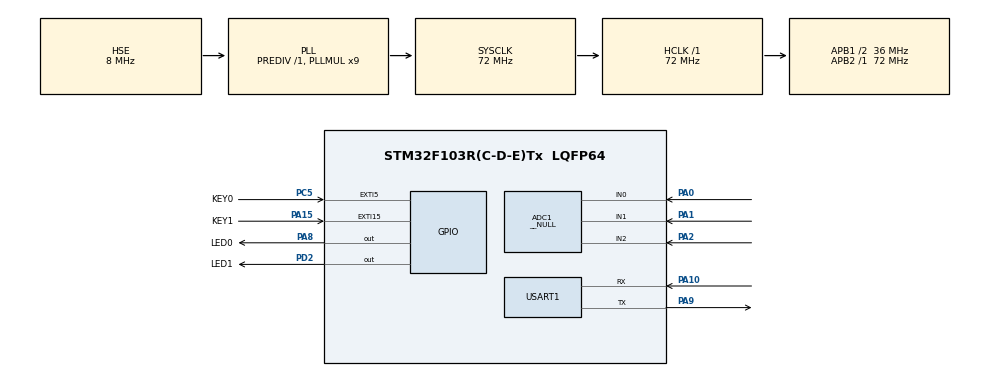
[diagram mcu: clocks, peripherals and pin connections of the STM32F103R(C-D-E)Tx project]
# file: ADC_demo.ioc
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Mcu.Family=STM32F1
ADC1.Rank-14\#ChannelRegularConversion=4
VP_ADC1_TempSens_Input.Mode=IN-TempSens
ADC1.ContinuousConvMode=ENABLE
SH.ADCx_IN2.0=ADC1_IN2,IN2
ADC1.Channel-14\#ChannelRegularConversion=ADC_CHANNEL_TEMPSENSOR
RCC.SYSCLKSource=RCC_SYSCLKSOURCE_PLLCLK
ProjectManager.StackSize=0x400
PD1-OSC_OUT.Signal=RCC_OSC_OUT
PA15.GPIO_Label=KEY1
PA15.GPIO_ModeDefaultEXTI=GPIO_MODE_IT_RISING
ADC1.Mode=__NULL
RCC.HCLKFreq_Value=72000000
RCC.APB2TimFreq_Value=72000000
Dma.ADC1.0.Direction=DMA_PERIPH_TO_MEMORY
ADC1.Channel-2\#ChannelRegularConversion=ADC_CHANNEL_2
Dma.ADC1.0.MemDataAlignment=DMA_MDATAALIGN_WORD
RCC.AHBFreq_Value=72000000
NVIC.EXTI15_10_IRQn=true\:0\:0\:false\:false\:true\:true\:true
ADC1.Channel-0\#ChannelRegularConversion=ADC_CHANNEL_0
PB3.Mode=Trace_Asynchronous_SW
RCC.PLLMUL=RCC_PLL_MUL9
ADC1.Rank-2\#ChannelRegularConversion=3
PC14-OSC32_IN.Mode=LSE-External-Oscillator
PA14.Mode=Trace_Asynchronous_SW
Dma.ADC1.0.PeriphInc=DMA_PINC_DISABLE
PA8.Signal=GPIO_Output
SH.ADCx_IN0.0=ADC1_IN0,IN0
ADC1.SamplingTime-0\#ChannelRegularConversion=ADC_SAMPLETIME_55CYCLES_5
Mcu.Package=LQFP64
NVIC.TimeBase=TIM7_IRQn
RCC.EnbaleCSS=true
NVIC.TimeBaseIP=TIM7
PA10.Signal=USART1_RX
PA15.Signal=GPXTI15
SH.ADCx_IN1.0=ADC1_IN1,IN1
RCC.APB1TimFreq_Value=72000000
PC5.Signal=GPXTI5
Dma.Request0=ADC1
NVIC.TIM7_IRQn=true\:0\:0\:false\:false\:true\:false\:true
PA8.PinState=GPIO_PIN_SET
RCC.PLLSourceVirtual=RCC_PLLSOURCE_HSE
PC15-OSC32_OUT.Mode=LSE-External-Oscillator
Dma.ADC1.0.Instance=DMA1_Channel1
ADC1.Rank-0\#ChannelRegularConversion=1
PD1-OSC_OUT.Mode=HSE-External-Oscillator
PA10.Mode=Asynchronous
PD2.GPIO_PuPd=GPIO_PULLDOWN
VP_SYS_VS_tim7.Mode=TIM7
PD0-OSC_IN.Signal=RCC_OSC_IN
RCC.APB1CLKDivider=RCC_HCLK_DIV2
PC14-OSC32_IN.Signal=RCC_OSC32_IN
PC5.GPIO_PuPd=GPIO_PULLUP
ADC1.SamplingTime-2\#ChannelRegularConversion=ADC_SAMPLETIME_55CYCLES_5
PA0-WKUP.Signal=ADCx_IN0
RCC.ADCPresc=RCC_ADCPCLK2_DIV6
PA13.Signal=SYS_JTMS-SWDIO
Dma.ADC1.0.PeriphDataAlignment=DMA_PDATAALIGN_WORD
PA9.Mode=Asynchronous
PA8.GPIO_Label=LED0
ProjectManager.TargetToolchain=STM32CubeIDE
Dma.ADC1.0.Mode=DMA_CIRCULAR
Dma.ADC1.0.Priority=DMA_PRIORITY_LOW
PA9.Signal=USART1_TX
ADC1.Channel-1\#ChannelRegularConversion=ADC_CHANNEL_1
RCC.USBFreq_Value=72000000
PC15-OSC32_OUT.Signal=RCC_OSC32_OUT
PA1.Signal=ADCx_IN1
PC5.GPIO_ModeDefaultEXTI=GPIO_MODE_IT_RISING
PD0-OSC_IN.Mode=HSE-External-Oscillator
PD2.PinState=GPIO_PIN_SET
board=custom
ADC1.SamplingTime-14\#ChannelRegularConversion=ADC_SAMPLETIME_55CYCLES_5
ADC1.EnableAnalogWatchDog=false
RCC.APB2Freq_Value=72000000
ADC1.NbrOfConversion=4
PA13.Mode=Trace_Asynchronous_SW
Mcu.Name=STM32F103R(C-D-E)Tx
PA2.Signal=ADCx_IN2
PB3.Signal=SYS_JTDO-TRACESWO
ADC1.SamplingTime-1\#ChannelRegularConversion=ADC_SAMPLETIME_55CYCLES_5
RCC.SYSCLKFreq_VALUE=72000000
ADC1.master=1
PC5.GPIO_Label=KEY0
USART1.VirtualMode=VM_ASYNC
ADC1.Rank-1\#ChannelRegularConversion=2
NVIC.EXTI9_5_IRQn=true\:0\:0\:false\:false\:true\:true\:true
PA14.Signal=SYS_JTCK-SWCLK
Dma.ADC1.0.MemInc=DMA_MINC_ENABLE
ProjectManager.HeapSize=0x200
PA8.GPIO_PuPd=GPIO_PULLDOWN
NVIC.PriorityGroup=NVIC_PRIORITYGROUP_4
ADC1.NbrOfConversionFlag=1
PA15.GPIO_PuPd=GPIO_PULLUP
NVIC.DMA1_Channel1_IRQn=true\:1\:0\:true\:false\:true\:false\:true
PD2.Signal=GPIO_Output
RCC.APB1Freq_Value=36000000
PD2.GPIO_Label=LED1

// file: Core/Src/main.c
/* USER CODE BEGIN Header */
/**
  ******************************************************************************
  * @file           : main.c
  * @brief          : Main program body
  ******************************************************************************
  * @attention
  *
  * <h2><center>&copy; Copyright (c) 2020 STMicroelectronics.
  * All rights reserved.</center></h2>
  *
  * This software component is licensed by ST under BSD 3-Clause license,
  * the "License"; You may not use this file except in compliance with the
  * License. You may obtain a copy of the License at:
  *                        opensource.org/licenses/BSD-3-Clause
  *
  ******************************************************************************
  */
/* USER CODE END Header */
#include "main.h"
#include "adc.h"
#include "dma.h"
#include "usart.h"
#include "gpio.h"

/* USER CODE BEGIN Includes */
#include "bsp_debug.h"
#include "bsp_led.h"
#include "KalmanFilter.h"
/* USER CODE END Includes */

/* USER CODE BEGIN PV */
__IO uint32_t ADC_value[4] = {0};
float ADC_IN1_value = 0;
uint8_t ADC_IN1_FaultCode = 0;
/* USER CODE END PV */

void SystemClock_Config(void);

int main(void)
{

  /* MCU Configuration--------------------------------------------------------*/

  /* Reset of all peripherals, Initializes the Flash interface and the Systick. */
  HAL_Init();

  /* Configure the system clock */
  SystemClock_Config();

  /* Initialize all configured peripherals */
  MX_GPIO_Init();
  MX_DMA_Init();
  MX_ADC1_Init();
  MX_USART1_UART_Init();
  /* USER CODE BEGIN 2 */
  ADC_KalmanFilter_Init();
  /* USER CODE END 2 */

  /* Infinite loop */
  /* USER CODE BEGIN WHILE */
  if(HAL_ADC_Start_DMA(&hadc1, (uint32_t*)ADC_value, 4) != HAL_OK)
  {
    Error_Handler();
  }

  while (1)
  {
    /* USER CODE END WHILE */

    /* USER CODE BEGIN 3 */
	  ADC_IN1_value = KalmanFilter(&ADC1_IN1_KalmanFilter, (float)ADC_value[0]);
	  ADC_IN1_FaultCode = (uint8_t)(16 * (ADC_IN1_value/4095));
  }
  /* USER CODE END 3 */
}

void SystemClock_Config(void)
{
  RCC_OscInitTypeDef RCC_OscInitStruct = {0};
  RCC_ClkInitTypeDef RCC_ClkInitStruct = {0};
  RCC_PeriphCLKInitTypeDef PeriphClkInit = {0};

  /** Initializes the RCC Oscillators according to the specified parameters
  * in the RCC_OscInitTypeDef structure.
  */
  RCC_OscInitStruct.OscillatorType = RCC_OSCILLATORTYPE_HSE;
  RCC_OscInitStruct.HSEState = RCC_HSE_ON;
  RCC_OscInitStruct.HSEPredivValue = RCC_HSE_PREDIV_DIV1;
  RCC_OscInitStruct.HSIState = RCC_HSI_ON;
  RCC_OscInitStruct.PLL.PLLState = RCC_PLL_ON;
  RCC_OscInitStruct.PLL.PLLSource = RCC_PLLSOURCE_HSE;
  RCC_OscInitStruct.PLL.PLLMUL = RCC_PLL_MUL9;
  if (HAL_RCC_OscConfig(&RCC_OscInitStruct) != HAL_OK)
  {
    Error_Handler();
  }
  /** Initializes the CPU, AHB and APB buses clocks
  */
  RCC_ClkInitStruct.ClockType = RCC_CLOCKTYPE_HCLK|RCC_CLOCKTYPE_SYSCLK
                              |RCC_CLOCKTYPE_PCLK1|RCC_CLOCKTYPE_PCLK2;
  RCC_ClkInitStruct.SYSCLKSource = RCC_SYSCLKSOURCE_PLLCLK;
  RCC_ClkInitStruct.AHBCLKDivider = RCC_SYSCLK_DIV1;
  RCC_ClkInitStruct.APB1CLKDivider = RCC_HCLK_DIV2;
  RCC_ClkInitStruct.APB2CLKDivider = RCC_HCLK_DIV1;

  if (HAL_RCC_ClockConfig(&RCC_ClkInitStruct, FLASH_LATENCY_2) != HAL_OK)
  {
    Error_Handler();
  }
  PeriphClkInit.PeriphClockSelection = RCC_PERIPHCLK_ADC;
  PeriphClkInit.AdcClockSelection = RCC_ADCPCLK2_DIV6;
  if (HAL_RCCEx_PeriphCLKConfig(&PeriphClkInit) != HAL_OK)
  {
    Error_Handler();
  }
  /** Enables the Clock Security System
  */
  HAL_RCC_EnableCSS();
}

void HAL_TIM_PeriodElapsedCallback(TIM_HandleTypeDef *htim)
{
  if (htim->Instance == TIM7) {
    HAL_IncTick();
  }
}

void Error_Handler(void)
{
}

/************************ (C) COPYRIGHT STMicroelectronics *****END OF FILE****/
